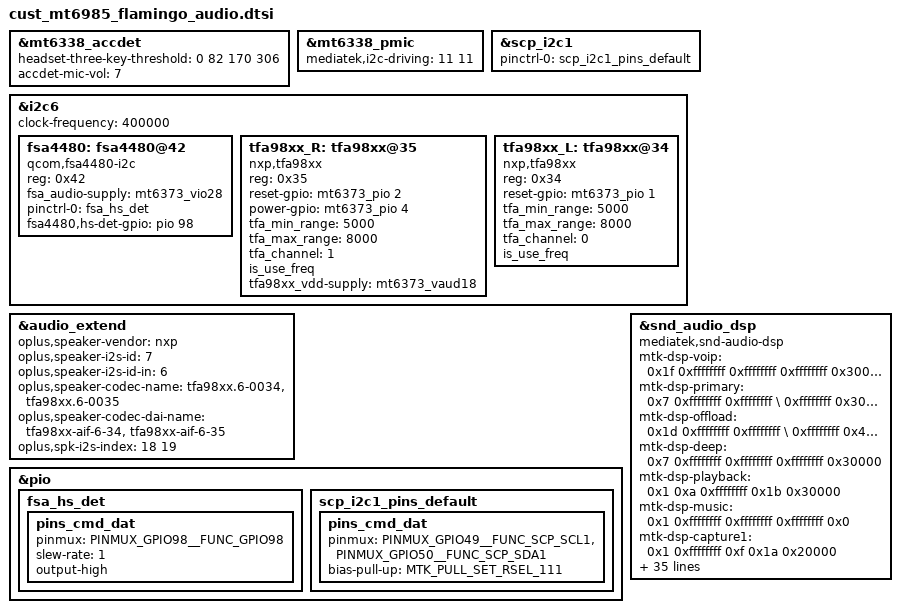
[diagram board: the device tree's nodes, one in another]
// SPDX-License-Identifier: GPL-2.0
/* Copyright (c) 2020 MediaTek Inc. */

&mt6338_accdet {
	headset-three-key-threshold = <0 82 170 306>;
	accdet-mic-vol = <7>;
};

&mt6338_pmic {
	mediatek,i2c-driving = <11 11>;
};

&scp_i2c1{
	pinctrl-names = "default";
	pinctrl-0 = <&scp_i2c1_pins_default>;
};

&i2c6 {
	clock-frequency = <400000>;

	fsa4480: fsa4480@42 {
		compatible = "qcom,fsa4480-i2c";
		reg = <0x42>;
		fsa_audio-supply = <&mt6373_vio28>;
		pinctrl-names = "default";
		pinctrl-0 = <&fsa_hs_det>;
		fsa4480,hs-det-gpio = <&pio 98 0>;
	};

	tfa98xx_R: tfa98xx@35 {
		compatible = "nxp,tfa98xx";
		reg = <0x35>;
		reset-gpio = <&mt6373_pio 2 0>;
		power-gpio = <&mt6373_pio 4 0>;
		tfa_min_range = <5000>;
		tfa_max_range = <8000>;
		tfa_channel = <1>;
		is_use_freq;
		tfa98xx_vdd-supply = <&mt6373_vaud18>;
		status = "okay";
	};

	tfa98xx_L: tfa98xx@34 {
		compatible = "nxp,tfa98xx";
		reg = <0x34>;
		reset-gpio = <&mt6373_pio 1 0>;
		tfa_min_range = <5000>;
		tfa_max_range = <8000>;
		tfa_channel = <0>;
		is_use_freq;
		status = "okay";
	};
};

&audio_extend {
 	//for nxp speaker
 	oplus,speaker-vendor = "nxp";
	oplus,speaker-i2s-id = <7>;
	oplus,speaker-i2s-id-in = <6>;
 	oplus,speaker-codec-name = "tfa98xx.6-0034","tfa98xx.6-0035";
 	oplus,speaker-codec-dai-name = "tfa98xx-aif-6-34","tfa98xx-aif-6-35";
	oplus,spk-i2s-index = <18 19>;
};

&pio {
	fsa_hs_det: fsa_hs_det {
		pins_cmd_dat {
			pinmux = <PINMUX_GPIO98__FUNC_GPIO98>;
			slew-rate = <1>;  /*direction 0:in, 1:out*/
			output-high;
		};
	};

	scp_i2c1_pins_default: scp_i2c1_pins_default {
		pins_cmd_dat {
			pinmux = <PINMUX_GPIO49__FUNC_SCP_SCL1>,
					<PINMUX_GPIO50__FUNC_SCP_SDA1>;
			/* 0x0: 75k    0x1: 10k */
			/* 0x2: 5k      0x3: 4k     0x4:3k*/
			/* 0x5: 2k   0x6: 1.5k   0x7:1k*/
			bias-pull-up = <MTK_PULL_SET_RSEL_111>;
		};
	};
};


/* feature : $enable $dl_mem $ul_mem $ref_mem $size */
&snd_audio_dsp {
	compatible = "mediatek,snd-audio-dsp";
	mtk-dsp-voip = <0x1f 0xffffffff 0xffffffff 0xffffffff 0x30000>;
	mtk-dsp-primary = <0x7 0xffffffff 0xffffffff \
			   0xffffffff 0x30000>;
	mtk-dsp-offload = <0x1d 0xffffffff 0xffffffff \
			   0xffffffff 0x400000>;
	mtk-dsp-deep = <0x7 0xffffffff 0xffffffff 0xffffffff 0x30000>;
	mtk-dsp-playback = <0x1 0xa 0xffffffff 0x1b 0x30000>;
	mtk-dsp-music = <0x1 0xffffffff 0xffffffff 0xffffffff 0x0>;
	mtk-dsp-capture1 = <0x1 0xffffffff 0xf 0x1a 0x20000>;
	mtk-dsp-a2dp = <0x1 0xffffffff 0xffffffff 0xffffffff 0x40000>;
	mtk-dsp-bledl = <0x1 0xffffffff 0xffffffff 0xffffffff 0x30000>;
	mtk-dsp-dataprovider = <0x0 0xffffffff 0x11 0xffffffff 0x30000>;
	mtk-dsp-call-final = <0x5 0xa 0x12 0x1b 0x18000>;
	mtk-dsp-fast = <0x7 0xffffffff 0xffffffff 0xffffffff 0x5000>;
	mtk-dsp-spatializer = <0x1f 0xffffffff 0xffffffff 0xffffffff 0x5000>;
	mtk-dsp-ktv = <0x1 0x8 0x14 0xffffffff 0x10000>;
	mtk-dsp-capture-raw = <0x1 0xffffffff 0xffffffff 0xffffffff 0x20000>;
	mtk-dsp-fm = <0x0 0xffffffff 0x12 0xffffffff 0x10000>;
	mtk-dsp-bleul = <0x0 0xffffffff 0xffffffff 0xffffffff 0x20000>;
	mtk-dsp-ulproc = <0x1 0xffffffff 0xffffffff 0xffffffff 0x20000>;
	mtk-dsp-echoref = <0x1 0xffffffff 0x1a 0xffffffff 0x20000>;
	mtk-dsp-echodl = <0x1 0x6 0xffffffff 0xffffffff 0x30000>;
	mtk-dsp-usbdl = <0x1 0xffffffff 0xffffffff 0xffffffff 0x30000>;
	mtk-dsp-usbul = <0x1 0xffffffff 0xffffffff 0xffffffff 0x30000>;
	mtk-dsp-a2dp-irq = <0x1>;
	mtk-dsp-ver = <0x1>;
	swdsp-smartpa-process-enable = <0x5>;
	mtk-dsp-mem-afe = <0x1 0x40000>;
	mtk-dsp-btdl = <0x1 0xb 0xffffffff 0xffffffff 0x30000>;
	mtk-dsp-btul = <0x1 0xffffffff 0x19 0x1a 0x20000>;
};
